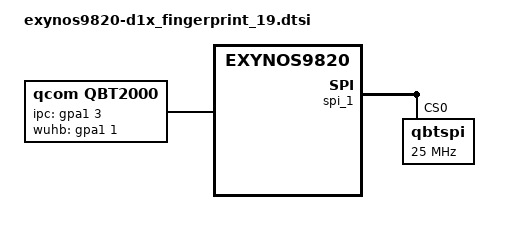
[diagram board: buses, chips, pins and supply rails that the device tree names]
/*
 * Copyright (c) 2012-2013, The Linux Foundation. All rights reserved.
 *
 * This program is free software; you can redistribute it and/or modify
 * it under the terms of the GNU General Public License version 2 and
 * only version 2 as published by the Free Software Foundation.
 *
 * This program is distributed in the hope that it will be useful,
 * but WITHOUT ANY WARRANTY; without even the implied warranty of
 * MERCHANTABILITY or FITNESS FOR A PARTICULAR PURPOSE.  See the
 * GNU General Public License for more details.
 */

&pinctrl_0 {
	btp_ipc: btp-ipc {
		samsung,pins = "gpa1-3";
		samsung,pin-function = <0xf>;
		samsung,pin-pud = <3>;
		samsung,pin-drv = <3>;
	};
	btp_wuhb: btp-wuhb {
		samsung,pins = "gpa1-1";
		samsung,pin-function = <0xf>;
		samsung,pin-pud = <1>;
		samsung,pin-drv = <3>;
	};
};

/ {
	fragment@model {
		target-path = "/";
		__overlay__ {
			#address-cells = <2>;
			#size-cells = <1>;
			qbt2000 {
				compatible = "qcom,qbt2000";
				qcom,ipc-gpio = <&gpa1 3 0>;
				qcom,wuhb-gpio = <&gpa1 1 0>;
				qcom,btp-regulator = "VDD_BTP_1P8";
				qcom,position = "32.46,0.00,9.00,4.00,14.80,14.80,13.00,13.00,5.00";
				pinctrl-names = "default", "pins_poweron", "pins_poweroff";
				pinctrl-0 = <&btp_ipc &btp_wuhb>;
				pinctrl-1 = <&spi1_bus &spi1_cs_func_high>;
				pinctrl-2 = <&spi1_bus_sleep &spi1_cs>;
			};
		};
	};
};

&spi_1 {
	status = "okay";
	secure-mode;
	/delete-property/ swap-mode;
	#address-cells = <1>;
	#size-cells = <0>;

	/delete-property/ pinctrl-names;
	/delete-property/ pinctrl-0;

	dma-mode;
	dmas = <&pdma0 1 &pdma0 0>;

	qbtspi@0 {
		compatible = "qbtspi";
		reg = <0>;
		spi-max-frequency = <25000000>;

		gpio-controller;
		#gpio-cells = <2>;
		controller-data {
			samsung,spi-feedback-delay = <0>;
			samsung,spi-chip-select-mode = <0>;
		};
	};
};
